# STM32F0xx register map
File version: 1.0
Registers are 32-bit, read-write, reset 0x0 unless marked. A register's access mark holds for its fields unless they carry their own. Offsets are from the block's base; [hi:lo] are bit positions; 'fields as' and 'values as' point back to an identical list.

## CEC — HDMI-CEC controller
Base 0x40007800
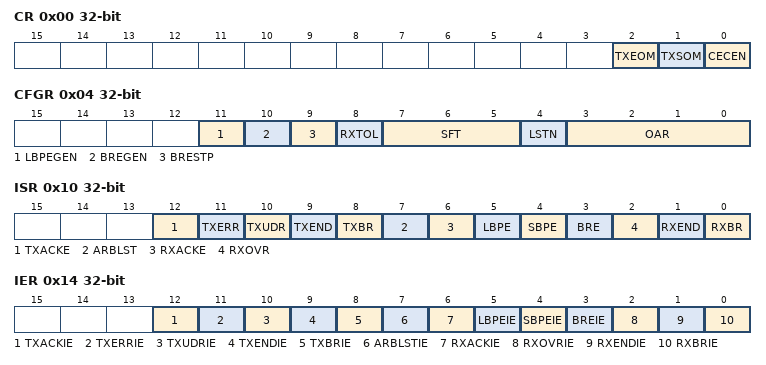
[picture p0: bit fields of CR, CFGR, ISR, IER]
0x00 CR — control register
  [2] TXEOM — Tx End Of Message
  [1] TXSOM — Tx start of message
  [0] CECEN — CEC Enable
    0=disabled (Disable the Rising trigger.); 1=enabled (Enable the Rising trigger.)
0x04 CFGR — configuration register
  [11] LBPEGEN — Generate Error-Bit on Long Bit Period Error
    values as CR.CECEN
  [10] BREGEN — Generate error-bit on bit rising error
    values as CR.CECEN
  [9] BRESTP — Rx-stop on bit rising error
  [8] RXTOL — Rx-Tolerance
  [7:5] SFT — Signal Free Time
  [4] LSTN — Listen mode
  [3:0] OAR — Own Address
0x08 TXDR wo — Tx data register
  [7:0] TXD — Tx Data register
0x0C RXDR ro — Rx Data Register
  [7:0] RXDR — CEC Rx Data Register
0x10 ISR — Interrupt and Status Register
  [12] TXACKE — Tx-Missing acknowledge error
  [11] TXERR — Tx-Error
  [10] TXUDR — Tx-Buffer Underrun
  [9] TXEND — End of Transmission
  [8] TXBR — Tx-Byte Request
  [7] ARBLST — Arbitration Lost
  [6] RXACKE — Rx-Missing Acknowledge
  [5] LBPE — Rx-Long Bit Period Error
  [4] SBPE — Rx-Short Bit period error
  [3] BRE — Rx-Bit rising error
  [2] RXOVR — Rx-Overrun
  [1] RXEND — End Of Reception
  [0] RXBR — Rx-Byte Received
0x14 IER — interrupt enable register
  [12] TXACKIE — Tx-Missing Acknowledge Error Interrupt Enable
  [11] TXERRIE — Tx-Error Interrupt Enable
  [10] TXUDRIE — Tx-Underrun interrupt enable
  [9] TXENDIE — Tx-End of message interrupt enable
  [8] TXBRIE — Tx-Byte Request Interrupt Enable
  [7] ARBLSTIE — Arbitration Lost Interrupt Enable
  [6] RXACKIE — Rx-Missing Acknowledge Error Interrupt Enable
  [5] LBPEIE — Long Bit Period Error Interrupt Enable
  [4] SBPEIE — Short Bit Period Error Interrupt Enable
  [3] BREIE — Bit Rising Error Interrupt Enable
  [2] RXOVRIE — Rx-Buffer Overrun Interrupt Enable
  [1] RXENDIE — End Of Reception Interrupt Enable
  [0] RXBRIE — Rx-Byte Received Interrupt Enable

## Flash
Base 0x40022000
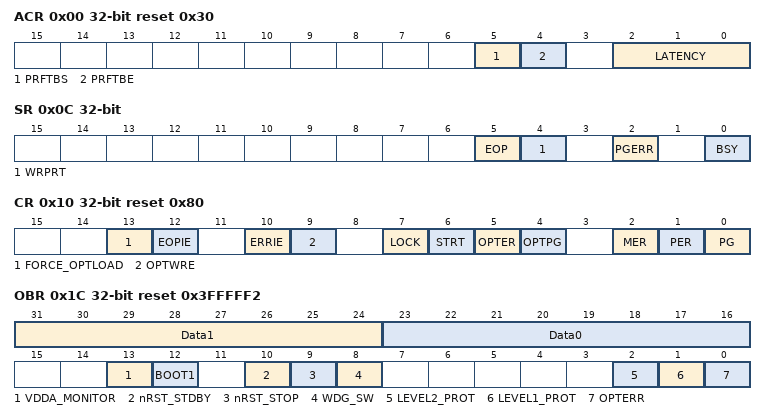
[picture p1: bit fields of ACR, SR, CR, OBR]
0x00 ACR access per field reset 0x30 — Flash access control register
  [5] PRFTBS ro, [4] PRFTBE rw, [2:0] LATENCY rw
0x04 KEYR wo — Flash key register
  [31:0] FKEYR — Flash Key
0x08 OPTKEYR wo — Flash option key register
  [31:0] OPTKEYR — Option byte key
0x0C SR access per field — Flash status register
  [5] EOP rw — End of operation
  [4] WRPRT rw — Write protection error
  [2] PGERR rw — Programming error
  [0] BSY ro — Busy
0x10 CR reset 0x80 — Flash control register
  [13] FORCE_OPTLOAD — Force option byte loading
  [12] EOPIE — End of operation interrupt enable
  [10] ERRIE — Error interrupt enable
  [9] OPTWRE — Option bytes write enable
  [7] LOCK
  [6] STRT — Start
  [5] OPTER — Option byte erase
  [4] OPTPG — Option byte programming
  [2] MER — Mass erase
  [1] PER — Page erase
  [0] PG — Programming
0x14 AR wo — Flash address register
  [31:0] FAR — Flash address
0x1C OBR ro reset 0x3FFFFF2 — Option byte register
  [31:24] Data1
  [23:16] Data0
  [13] VDDA_MONITOR
  [12] BOOT1
  [10] nRST_STDBY
  [9] nRST_STOP
  [8] WDG_SW
  [2] LEVEL2_PROT — Level 2 protection status
  [1] LEVEL1_PROT — Level 1 protection status
  [0] OPTERR — Option byte error
0x20 WRPR ro reset 0xFFFFFFFF — Write protection register
  [15:0] WRP — Write protect

## DBGMCU — Debug support
Base 0x40015800
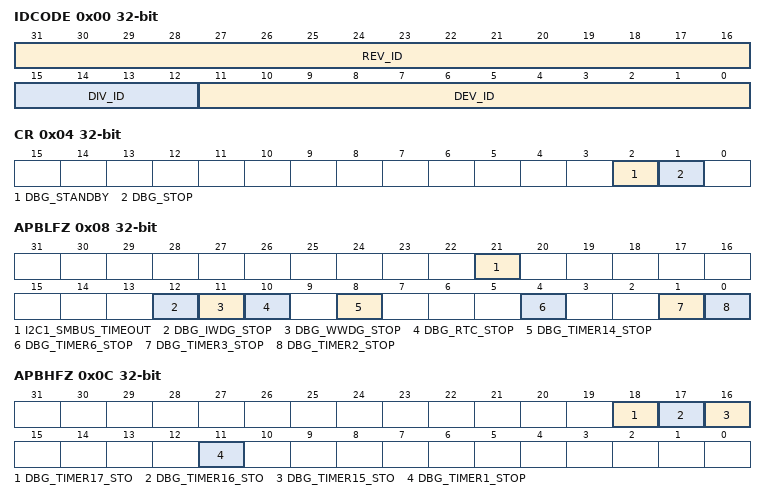
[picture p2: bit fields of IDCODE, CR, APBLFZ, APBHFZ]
0x00 IDCODE ro — MCU Device ID Code Register
  [31:16] REV_ID — Revision Identifier
  [15:12] DIV_ID — Division Identifier
  [11:0] DEV_ID — Device Identifier
0x04 CR — Debug MCU Configuration Register
  [2] DBG_STANDBY — Debug Standby Mode
  [1] DBG_STOP — Debug Stop Mode
0x08 APBLFZ — APB Low Freeze Register
  [21] I2C1_SMBUS_TIMEOUT — SMBUS timeout mode stopped when Core is halted
  [12] DBG_IWDG_STOP — Debug Independent Wachdog stopped when Core is halted
  [11] DBG_WWDG_STOP — Debug Window Wachdog stopped when Core is halted
  [10] DBG_RTC_STOP — Debug RTC stopped when Core is halted
  [8] DBG_TIMER14_STOP — Debug Timer 14 stopped when Core is halted
  [4] DBG_TIMER6_STOP — Debug Timer 6 stopped when Core is halted
  [1] DBG_TIMER3_STOP — Debug Timer 3 stopped when Core is halted
  [0] DBG_TIMER2_STOP — Debug Timer 2 stopped when Core is halted
0x0C APBHFZ — APB High Freeze Register
  [18] DBG_TIMER17_STO — Debug Timer 17 stopped when Core is halted
  [17] DBG_TIMER16_STO — Debug Timer 16 stopped when Core is halted
  [16] DBG_TIMER15_STO — Debug Timer 15 stopped when Core is halted
  [11] DBG_TIMER1_STOP — Debug Timer 1 stopped when Core is halted
